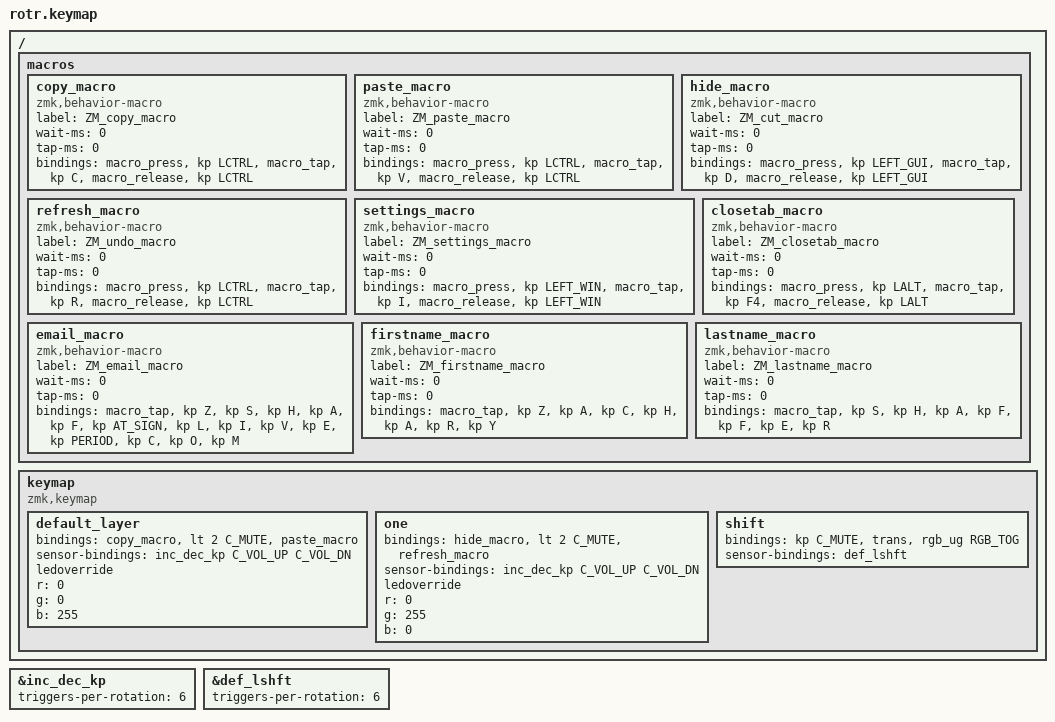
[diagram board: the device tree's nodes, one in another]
#include <behaviors.dtsi>
#include <dt-bindings/zmk/keys.h>
#include <dt-bindings/zmk/rgb.h>
#include <dt-bindings/zmk/bt.h>

&inc_dec_kp {
	triggers-per-rotation = <6>;
};
&def_lshft {
	triggers-per-rotation = <6>;
};

/ {
	macros {
		copy_macro: copy_macro {
		compatible = "zmk,behavior-macro";
		label = "ZM_copy_macro";
		#binding-cells = <0>;
		wait-ms = <0>;
		tap-ms = <0>;
		bindings
			= <&macro_press &kp LCTRL>
			, <&macro_tap &kp C>
			, <&macro_release &kp LCTRL>
			;
		};
		paste_macro: paste_macro {
		compatible = "zmk,behavior-macro";
		label = "ZM_paste_macro";
		#binding-cells = <0>;
		wait-ms = <0>;
		tap-ms = <0>;
		bindings
			= <&macro_press &kp LCTRL>
			, <&macro_tap &kp V>
			, <&macro_release &kp LCTRL>
			;
		};
		hide_macro: hide_macro {
		compatible = "zmk,behavior-macro";
		label = "ZM_cut_macro";
		#binding-cells = <0>;
		wait-ms = <0>;
		tap-ms = <0>;
		bindings
			= <&macro_press &kp LEFT_GUI>
			, <&macro_tap &kp D>
			, <&macro_release &kp LEFT_GUI>
			;
		};
		refresh_macro: refresh_macro {
		compatible = "zmk,behavior-macro";
		label = "ZM_undo_macro";
		#binding-cells = <0>;
		wait-ms = <0>;
		tap-ms = <0>;
		bindings
			= <&macro_press &kp LCTRL>
			, <&macro_tap &kp R>
			, <&macro_release &kp LCTRL>
			;
		};
		settings_macro: settings_macro {
		compatible = "zmk,behavior-macro";
		label = "ZM_settings_macro";
		#binding-cells = <0>;
		wait-ms = <0>;
		tap-ms = <0>;
		bindings
			= <&macro_press &kp LEFT_WIN>
			, <&macro_tap &kp I>
			, <&macro_release &kp LEFT_WIN>
			;
		};
		closetab_macro: closetab_macro {
		compatible = "zmk,behavior-macro";
		label = "ZM_closetab_macro";
		#binding-cells = <0>;
		wait-ms = <0>;
		tap-ms = <0>;
		bindings
			= <&macro_press &kp LALT>
			, <&macro_tap &kp F4>
			, <&macro_release &kp LALT>
			;
		};
		email_macro: email_macro {
		compatible = "zmk,behavior-macro";
		label = "ZM_email_macro";
		#binding-cells = <0>;
		wait-ms = <0>;
		tap-ms = <0>;
		bindings
			= <&macro_tap &kp Z &kp S &kp H &kp A &kp F &kp AT_SIGN &kp L &kp I &kp V &kp E &kp PERIOD &kp C &kp O &kp M>
			;
		};
		firstname_macro: firstname_macro {
		compatible = "zmk,behavior-macro";
		label = "ZM_firstname_macro";
		#binding-cells = <0>;
		wait-ms = <0>;
		tap-ms = <0>;
		bindings
			= <&macro_tap &kp Z &kp A &kp C &kp H &kp A &kp R &kp Y>
			;
		};
		lastname_macro: lastname_macro {
		compatible = "zmk,behavior-macro";
		label = "ZM_lastname_macro";
		#binding-cells = <0>;
		wait-ms = <0>;
		tap-ms = <0>;
		bindings
			= <&macro_tap &kp S &kp H &kp A &kp F &kp F &kp E &kp R>
			;
		};
	};
};

/ {
	keymap {
		compatible = "zmk,keymap";
		default_layer {
			//PREV | PLAY/PAUSE | NEXT
			bindings = <&copy_macro &lt 2 C_MUTE &paste_macro>;
			sensor-bindings = <&inc_dec_kp C_VOL_UP C_VOL_DN>;
			ledoverride;
			r = <0>;
			g = <0>;
			b = <255>;
		};
		one {
			//PREV | PLAY/PAUSE | NEXT
			bindings = <&hide_macro &lt 2 C_MUTE &refresh_macro>;
			sensor-bindings = <&inc_dec_kp C_VOL_UP C_VOL_DN>;
			ledoverride;
			r = <0>;
			g = <255>;
			b = <0>;
		};
		shift {
			//PREV | PLAY/PAUSE | NEXT
			bindings = <&kp C_MUTE &trans &rgb_ug RGB_TOG>;
			sensor-bindings = <&def_lshft>;
		};
	};
};
